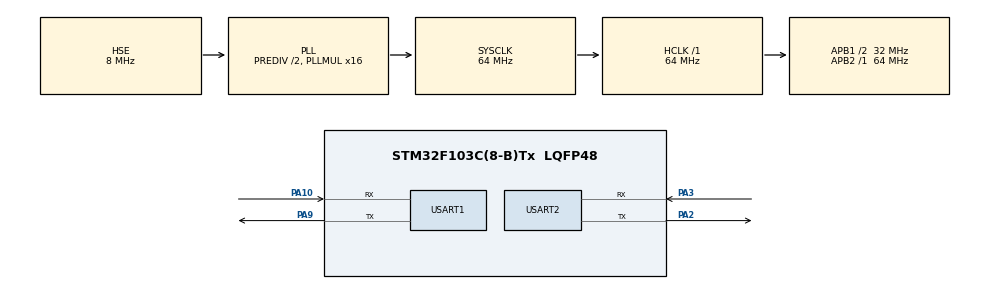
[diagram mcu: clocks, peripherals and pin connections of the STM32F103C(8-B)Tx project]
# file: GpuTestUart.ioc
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Dma.Request0=USART1_TX
Dma.Request1=USART2_TX
Dma.USART1_TX.0.Direction=DMA_MEMORY_TO_PERIPH
Dma.USART1_TX.0.Instance=DMA1_Channel4
Dma.USART1_TX.0.MemDataAlignment=DMA_MDATAALIGN_BYTE
Dma.USART1_TX.0.MemInc=DMA_MINC_ENABLE
Dma.USART1_TX.0.Mode=DMA_NORMAL
Dma.USART1_TX.0.PeriphDataAlignment=DMA_PDATAALIGN_BYTE
Dma.USART1_TX.0.PeriphInc=DMA_PINC_DISABLE
Dma.USART1_TX.0.Priority=DMA_PRIORITY_LOW
Dma.USART2_TX.1.Direction=DMA_MEMORY_TO_PERIPH
Dma.USART2_TX.1.Instance=DMA1_Channel7
Dma.USART2_TX.1.MemDataAlignment=DMA_MDATAALIGN_BYTE
Dma.USART2_TX.1.MemInc=DMA_MINC_ENABLE
Dma.USART2_TX.1.Mode=DMA_NORMAL
Dma.USART2_TX.1.PeriphDataAlignment=DMA_PDATAALIGN_BYTE
Dma.USART2_TX.1.PeriphInc=DMA_PINC_DISABLE
Dma.USART2_TX.1.Priority=DMA_PRIORITY_LOW
FREERTOS.BinarySemaphores01=USART1_Send,Dynamic,NULL;USART2_Send,Dynamic,NULL;USART1_Rx,Dynamic,NULL
FREERTOS.INCLUDE_xSemaphoreGetMutexHolder=0
FREERTOS.Tasks01=defaultTask,24,1024,StartDefaultTask,Default,NULL,Dynamic,NULL,NULL;USART1_TX,48,256,usart1TxTask,As weak,NULL,Dynamic,NULL,NULL;USART2_TX,49,512,Usart2TxTask,As weak,NULL,Dynamic,NULL,NULL;UC_SHELL_task,48,512,uc_shell_task,As weak,NULL,Dynamic,NULL,NULL
FREERTOS.configTOTAL_HEAP_SIZE=10240
Mcu.Family=STM32F1
Mcu.Name=STM32F103C(8-B)Tx
Mcu.Package=LQFP48
NVIC.DMA1_Channel4_IRQn=true\:5\:0\:false\:false\:true\:true\:false\:true
NVIC.DMA1_Channel7_IRQn=true\:5\:0\:false\:false\:true\:true\:false\:true
NVIC.PriorityGroup=NVIC_PRIORITYGROUP_4
NVIC.RTC_IRQn=true\:5\:0\:false\:false\:true\:true\:true\:true
NVIC.TIM4_IRQn=true\:0\:0\:false\:false\:true\:false\:false\:true
NVIC.TimeBase=TIM4_IRQn
NVIC.TimeBaseIP=TIM4
NVIC.USART1_IRQn=true\:5\:0\:false\:false\:true\:true\:true\:true
NVIC.USART2_IRQn=true\:5\:0\:false\:false\:true\:true\:true\:true
PA10.Mode=Asynchronous
PA10.Signal=USART1_RX
PA13.Mode=Serial_Wire
PA13.Signal=SYS_JTMS-SWDIO
PA14.Mode=Serial_Wire
PA14.Signal=SYS_JTCK-SWCLK
PA2.Mode=Asynchronous
PA2.Signal=USART2_TX
PA3.Mode=Asynchronous
PA3.Signal=USART2_RX
PA9.Mode=Asynchronous
PA9.Signal=USART1_TX
PC14-OSC32_IN.Mode=LSE-External-Oscillator
PC14-OSC32_IN.Signal=RCC_OSC32_IN
PC15-OSC32_OUT.Mode=LSE-External-Oscillator
PC15-OSC32_OUT.Signal=RCC_OSC32_OUT
PD0-OSC_IN.Mode=HSE-External-Oscillator
PD0-OSC_IN.Signal=RCC_OSC_IN
PD1-OSC_OUT.Mode=HSE-External-Oscillator
PD1-OSC_OUT.Signal=RCC_OSC_OUT
ProjectManager.HeapSize=0x200
ProjectManager.StackSize=0x400
ProjectManager.TargetToolchain=EWARM V8.32
RCC.AHBFreq_Value=64000000
RCC.APB1CLKDivider=RCC_HCLK_DIV2
RCC.APB1Freq_Value=32000000
RCC.APB1TimFreq_Value=64000000
RCC.APB2Freq_Value=64000000
RCC.APB2TimFreq_Value=64000000
RCC.HCLKFreq_Value=64000000
RCC.HSEDivPLL=RCC_HSE_PREDIV_DIV2
RCC.PLLMUL=RCC_PLL_MUL16
RCC.PLLSourceVirtual=RCC_PLLSOURCE_HSE
RCC.RTCClockSelection=RCC_RTCCLKSOURCE_LSE
RCC.SYSCLKFreq_VALUE=64000000
RCC.SYSCLKSource=RCC_SYSCLKSOURCE_PLLCLK
RCC.USBFreq_Value=64000000
USART1.VirtualMode=VM_ASYNC
USART2.VirtualMode=VM_ASYNC
VP_FREERTOS_VS_CMSIS_V2.Mode=CMSIS_V2
VP_RTC_VS_RTC_Activate.Mode=RTC_Enabled
VP_SYS_VS_tim4.Mode=TIM4
board=custom

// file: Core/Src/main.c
/* USER CODE BEGIN Header */
/**
  ******************************************************************************
  * @file           : main.c
  * @brief          : Main program body
  ******************************************************************************
  * @attention
  *
  * <h2><center>&copy; Copyright (c) 2020 STMicroelectronics.
  * All rights reserved.</center></h2>
  *
  * This software component is licensed by ST under Ultimate Liberty license
  * SLA0044, the "License"; You may not use this file except in compliance with
  * the License. You may obtain a copy of the License at:
  *                             www.st.com/SLA0044
  *
  ******************************************************************************
  */
/* USER CODE END Header */

#include "main.h"
#include "cmsis_os.h"
#include "dma.h"
#include "rtc.h"
#include "usart.h"
#include "gpio.h"

void SystemClock_Config(void);
void MX_FREERTOS_Init(void);

int main(void)
{

  /* MCU Configuration--------------------------------------------------------*/

  /* Reset of all peripherals, Initializes the Flash interface and the Systick. */
  HAL_Init();

  /* Configure the system clock */
  SystemClock_Config();

  /* Initialize all configured peripherals */
  MX_GPIO_Init();
  MX_DMA_Init();
  MX_RTC_Init();
  MX_USART1_UART_Init();
  MX_USART2_UART_Init();

  /* Init scheduler */
  osKernelInitialize();  /* Call init function for freertos objects (in freertos.c) */
  MX_FREERTOS_Init();
  /* Start scheduler */
  osKernelStart();

  /* We should never get here as control is now taken by the scheduler */
  /* Infinite loop */
  while (1)
  {

  }
}

void SystemClock_Config(void)
{
  RCC_OscInitTypeDef RCC_OscInitStruct = {0};
  RCC_ClkInitTypeDef RCC_ClkInitStruct = {0};
  RCC_PeriphCLKInitTypeDef PeriphClkInit = {0};

  /** Initializes the CPU, AHB and APB busses clocks
  */
  RCC_OscInitStruct.OscillatorType = RCC_OSCILLATORTYPE_HSE|RCC_OSCILLATORTYPE_LSE;
  RCC_OscInitStruct.HSEState = RCC_HSE_ON;
  RCC_OscInitStruct.HSEPredivValue = RCC_HSE_PREDIV_DIV2;
  RCC_OscInitStruct.LSEState = RCC_LSE_ON;
  RCC_OscInitStruct.HSIState = RCC_HSI_ON;
  RCC_OscInitStruct.PLL.PLLState = RCC_PLL_ON;
  RCC_OscInitStruct.PLL.PLLSource = RCC_PLLSOURCE_HSE;
  RCC_OscInitStruct.PLL.PLLMUL = RCC_PLL_MUL16;
  if (HAL_RCC_OscConfig(&RCC_OscInitStruct) != HAL_OK)
  {
    Error_Handler();
  }
  /** Initializes the CPU, AHB and APB busses clocks
  */
  RCC_ClkInitStruct.ClockType = RCC_CLOCKTYPE_HCLK|RCC_CLOCKTYPE_SYSCLK
                              |RCC_CLOCKTYPE_PCLK1|RCC_CLOCKTYPE_PCLK2;
  RCC_ClkInitStruct.SYSCLKSource = RCC_SYSCLKSOURCE_PLLCLK;
  RCC_ClkInitStruct.AHBCLKDivider = RCC_SYSCLK_DIV1;
  RCC_ClkInitStruct.APB1CLKDivider = RCC_HCLK_DIV2;
  RCC_ClkInitStruct.APB2CLKDivider = RCC_HCLK_DIV1;

  if (HAL_RCC_ClockConfig(&RCC_ClkInitStruct, FLASH_LATENCY_2) != HAL_OK)
  {
    Error_Handler();
  }
  PeriphClkInit.PeriphClockSelection = RCC_PERIPHCLK_RTC;
  PeriphClkInit.RTCClockSelection = RCC_RTCCLKSOURCE_LSE;
  if (HAL_RCCEx_PeriphCLKConfig(&PeriphClkInit) != HAL_OK)
  {
    Error_Handler();
  }
}

 /**
  * @brief  Period elapsed callback in non blocking mode
  * @note   This function is called  when TIM4 interrupt took place, inside
  * HAL_TIM_IRQHandler(). It makes a direct call to HAL_IncTick() to increment
  * a global variable "uwTick" used as application time base.
  * @param  htim : TIM handle
  * @retval None
  */
void HAL_TIM_PeriodElapsedCallback(TIM_HandleTypeDef *htim)
{
  if (htim->Instance == TIM4) {
    HAL_IncTick();
  }
}

void Error_Handler(void)
{
}

/************************ (C) COPYRIGHT STMicroelectronics *****END OF FILE****/

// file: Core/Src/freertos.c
/* USER CODE BEGIN Header */
/**
  ******************************************************************************
  * File Name          : freertos.c
  * Description        : Code for freertos applications
  ******************************************************************************
  * @attention
  *
  * <h2><center>&copy; Copyright (c) 2020 STMicroelectronics.
  * All rights reserved.</center></h2>
  *
  * This software component is licensed by ST under Ultimate Liberty license
  * SLA0044, the "License"; You may not use this file except in compliance with
  * the License. You may obtain a copy of the License at:
  *                             www.st.com/SLA0044
  *
  ******************************************************************************
  */
/* USER CODE END Header */

#include "FreeRTOS.h"
#include "task.h"
#include "main.h"
#include "cmsis_os.h"

/* USER CODE BEGIN Includes */
#include "app_cfg.h"
/* USER CODE END Includes */

/* Definitions for defaultTask */
osThreadId_t defaultTaskHandle;
const osThreadAttr_t defaultTask_attributes = {
  .name = "defaultTask",
  .priority = (osPriority_t) osPriorityNormal,
  .stack_size = 1024 * 4
};
/* Definitions for USART1_TX */
osThreadId_t USART1_TXHandle;
const osThreadAttr_t USART1_TX_attributes = {
  .name = "USART1_TX",
  .priority = (osPriority_t) osPriorityRealtime,
  .stack_size = 256 * 4
};
/* Definitions for USART2_TX */
osThreadId_t USART2_TXHandle;
const osThreadAttr_t USART2_TX_attributes = {
  .name = "USART2_TX",
  .priority = (osPriority_t) osPriorityRealtime1,
  .stack_size = 512 * 4
};
/* Definitions for UC_SHELL_task */
osThreadId_t UC_SHELL_taskHandle;
const osThreadAttr_t UC_SHELL_task_attributes = {
  .name = "UC_SHELL_task",
  .priority = (osPriority_t) osPriorityRealtime,
  .stack_size = 512 * 4
};
/* Definitions for USART1_Send */
osSemaphoreId_t USART1_SendHandle;
const osSemaphoreAttr_t USART1_Send_attributes = {
  .name = "USART1_Send"
};
/* Definitions for USART2_Send */
osSemaphoreId_t USART2_SendHandle;
const osSemaphoreAttr_t USART2_Send_attributes = {
  .name = "USART2_Send"
};
/* Definitions for USART1_Rx */
osSemaphoreId_t USART1_RxHandle;
const osSemaphoreAttr_t USART1_Rx_attributes = {
  .name = "USART1_Rx"
};

/* USER CODE BEGIN FunctionPrototypes */

  /* Definitions for USART1_Rx */
//osSemaphoreId_t USART1_RxHandle;
//const osSemaphoreAttr_t USART1_Rx_attributes = {
//  .name = "USART1_Rx"
//};

/* USER CODE END FunctionPrototypes */

void StartDefaultTask(void *argument);
void usart1TxTask(void *argument);
void Usart2TxTask(void *argument);
void uc_shell_task(void *argument);

void MX_FREERTOS_Init(void); /* (MISRA C 2004 rule 8.1) */

void MX_FREERTOS_Init(void) {

  /* Create the semaphores(s) */
  /* creation of USART1_Send */
  USART1_SendHandle = osSemaphoreNew(1, 1, &USART1_Send_attributes);

  /* creation of USART2_Send */
  USART2_SendHandle = osSemaphoreNew(1, 1, &USART2_Send_attributes);

  /* creation of USART1_Rx */
//  USART1_RxHandle = osSemaphoreNew(1, 1, &USART1_Rx_attributes);

  /* USER CODE BEGIN RTOS_SEMAPHORES */
  /* add semaphores, ... */

  USART1_RxHandle = osSemaphoreNew(1, 0, &USART1_Rx_attributes);

  /* USER CODE END RTOS_SEMAPHORES */

  /* Create the thread(s) */
  /* creation of defaultTask */
  defaultTaskHandle = osThreadNew(StartDefaultTask, NULL, &defaultTask_attributes);

  /* creation of USART1_TX */
  USART1_TXHandle = osThreadNew(usart1TxTask, NULL, &USART1_TX_attributes);

  /* creation of USART2_TX */
  USART2_TXHandle = osThreadNew(Usart2TxTask, NULL, &USART2_TX_attributes);

  /* creation of UC_SHELL_task */
  UC_SHELL_taskHandle = osThreadNew(uc_shell_task, NULL, &UC_SHELL_task_attributes);

}

void StartDefaultTask(void *argument)
{
  /* USER CODE BEGIN StartDefaultTask */

  /* Infinite loop */

  for(;;)
  {
//    osMutexWait(USART1_TX_MutexHandle, portMAX_DELAY);
    osDelay(10);
extern void RxReceive(void *argument);
    RxReceive(NULL);
  }
  /* USER CODE END StartDefaultTask */
}

__weak void usart1TxTask(void *argument)
{
  for(;;)
  {
    osDelay(1);
  }
}

__weak void Usart2TxTask(void *argument)
{
  for(;;)
  {
    osDelay(1);
  }
}

__weak void uc_shell_task(void *argument)
{
  for(;;)
  {
    osDelay(1);
  }
}

/************************ (C) COPYRIGHT STMicroelectronics *****END OF FILE****/
